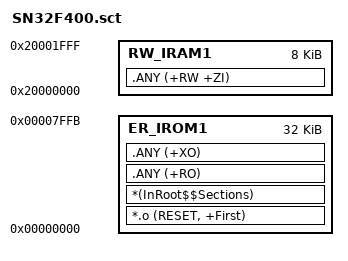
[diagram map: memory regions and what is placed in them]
; *************************************************************
; *** Scatter-Loading Description File for SN32F407 (VibraDistill) ***
; *************************************************************

LR_IROM1 0x00000000 0x00007FFC  {    ; load region size_region (32KB Flash - 4B ISP flag)
  ER_IROM1 0x00000000 0x00007FFC  {  ; load address = execution address
   *.o (RESET, +First)
   *(InRoot$$Sections)
   .ANY (+RO)
   .ANY (+XO)
  }
  RW_IRAM1 0x20000000 0x00002000  {  ; RW data (8KB SRAM)
   .ANY (+RW +ZI)
  }
}
